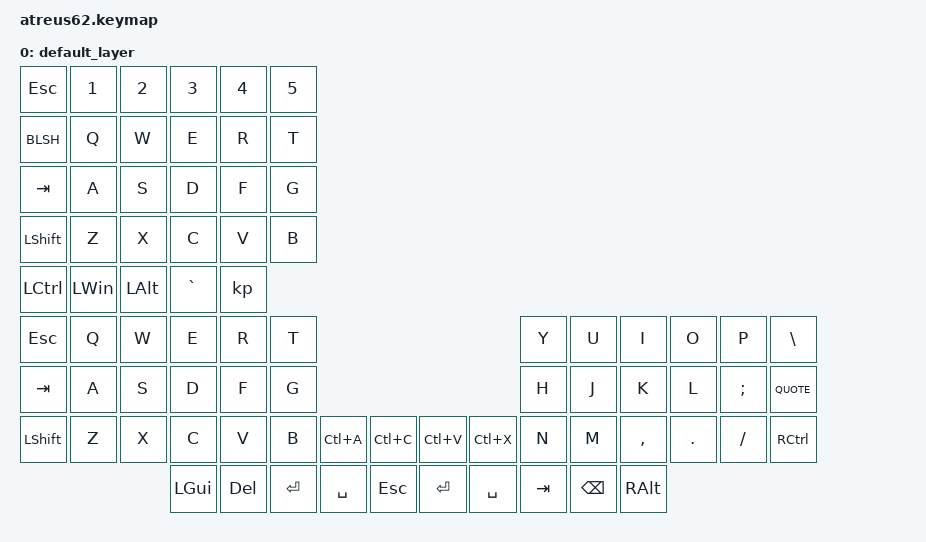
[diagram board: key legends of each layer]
#include <behaviors.dtsi>
#include <dt-bindings/zmk/keys.h>

/ {
    keymap {
        compatible = "zmk,keymap";

        default_layer {
// ----------------------------------------------------------------------------------------------------------------------------------------------------
// |   ESC   |    1    |    2    |    3    |    4    |    5    |                          |    6    |    7    |    8    |    9    |    0    |    -    |
// |    \    |    Q    |    W    |    E    |    R    |    T    |                          |    Y    |    U    |    I    |    O    |    P    |    ]    |
// |   TAB   |    A    |    S    |    D    |    F    |    G    |                          |    H    |    J    |    K    |    L    |    ;    |    '    |
// |  SHIFT  |    Z    |    X    |    C    |    V    |    B    |---------       ----------|    N    |    M    |    ,    |    .    |    /    |    [    |
// |   CTRL  |   WIN   |   ALT   |    `    |  MO(1)  |   BSPC  |   DEL  |       |  ENTER  |  SPACE  |    =    |    -    |    '    |  ENTER  |   WIN   |
// ----------------------------------------------------------------------------------------------------------------------------------------------------
            bindings = <
&kp ESC   &kp N1   &kp N2   &kp N3     &kp N4  &kp N5
&kp BLSH  &kp Q    &kp W    &kp E      &kp R   &kp T
&kp TAB   &kp A    &kp S    &kp D      &kp F   &kp G
&kp LSHFT &kp Z    &kp X    &kp C      &kp V   &kp B
&kp LCTRL &kp LWIN &kp LALT &kp GRAVE  &kp #?  &kp BSPC  &kp DEL  &kp ENTER  &kp SPACE  &kp EQUAL  &kp 

    &kp ESC   &kp Q     &kp W    &kp E     &kp R     &kp T                                                 &kp Y     &kp U     &kp I     &kp O     &kp P    &kp BSLH
    &kp TAB   &kp A     &kp S    &kp D     &kp F     &kp G                                                 &kp H     &kp J     &kp K     &kp L     &kp SEMI &kp QUOTE
    &kp LSHFT &kp Z     &kp X    &kp C     &kp V     &kp B      &kp LC(A) &kp LC(C)    &kp LC(V) &kp LC(X) &kp N     &kp M     &kp COMMA &kp DOT   &kp FSLH &kp RCTRL
                                 &kp LGUI  &kp DEL   &kp RET    &kp SPACE &kp ESC      &kp RET   &kp SPACE &kp TAB   &kp BSPC  &kp RALT
            >;

        };
    };
};
